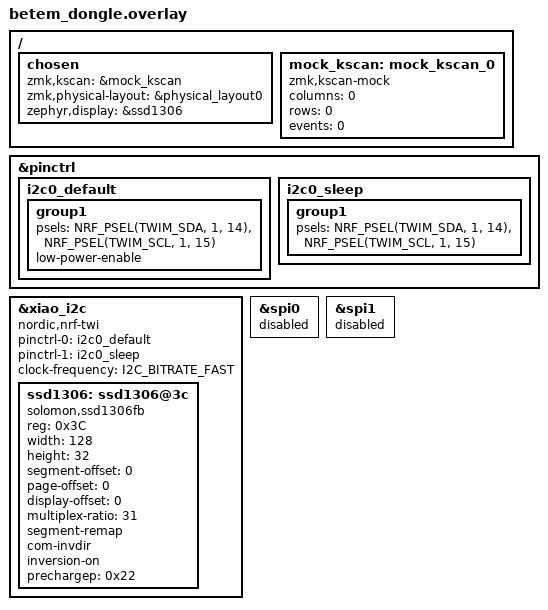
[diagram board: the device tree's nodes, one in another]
/*
 * Copyright (c) 2020 The ZMK Contributors
 *
 * SPDX-License-Identifier: MIT
 */
#include <dt-bindings/zmk/matrix_transform.h>
#include "betem-layouts.dtsi"

/ {
    chosen {
        zmk,kscan = &mock_kscan;
        zmk,physical-layout = &physical_layout0;
        zephyr,display = &ssd1306;
    };

    mock_kscan: mock_kscan_0 {
        compatible = "zmk,kscan-mock";
        columns = <0>;
        rows = <0>;
        events = <0>;
    };
};

&pinctrl {
    i2c0_default: i2c0_default {
        group1 {
            psels = <NRF_PSEL(TWIM_SDA, 1, 14)>,
                    <NRF_PSEL(TWIM_SCL, 1, 15)>;
            low-power-enable;
        };
    };

    i2c0_sleep: i2c0_sleep {
        group1 {
            psels = <NRF_PSEL(TWIM_SDA, 1, 14)>,
                    <NRF_PSEL(TWIM_SCL, 1, 15)>;
        };
    };
};

&xiao_i2c {
    compatible = "nordic,nrf-twi";
    status = "okay";
    pinctrl-0 = <&i2c0_default>;
    pinctrl-1 = <&i2c0_sleep>;
    pinctrl-names = "default", "sleep";
    clock-frequency = <I2C_BITRATE_FAST>;
    ssd1306: ssd1306@3c {
        compatible = "solomon,ssd1306fb";
        reg = <0x3C>;
        width = <128>;
        height = <32>;
        segment-offset = <0>;
        page-offset = <0>;
        display-offset = <0>;
        multiplex-ratio = <31>;
        segment-remap;
        com-invdir;
        inversion-on;
        prechargep = <0x22>;
    };
};

&spi0 {
    status = "disabled";
};

&spi1 {
    status = "disabled";
};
